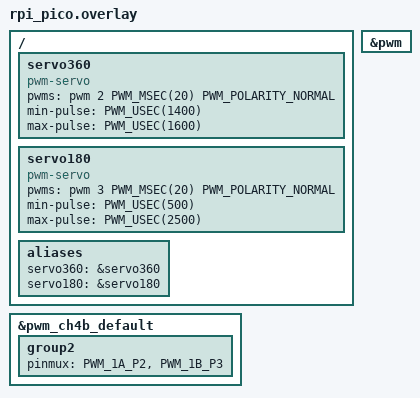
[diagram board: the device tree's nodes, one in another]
/ {
    servo360: servo360 {
        compatible = "pwm-servo";
        pwms = <&pwm 2 PWM_MSEC(20) PWM_POLARITY_NORMAL>;
        min-pulse = <PWM_USEC(1400)>;
        max-pulse = <PWM_USEC(1600)>;
    };

    servo180: servo180 {
        compatible = "pwm-servo";
        pwms = <&pwm 3 PWM_MSEC(20) PWM_POLARITY_NORMAL>;
        min-pulse = <PWM_USEC(500)>;
        max-pulse = <PWM_USEC(2500)>;
    };

    aliases {
        servo360 = &servo360;
        servo180 = &servo180;
    };
};

&pwm_ch4b_default {
    group2 {
        pinmux = <PWM_1A_P2>, /* FS90R (GPIO0) */
                 <PWM_1B_P3>; /* SG90  (GPIO1) */
    };
};

&pwm {
    status = "okay";
};

